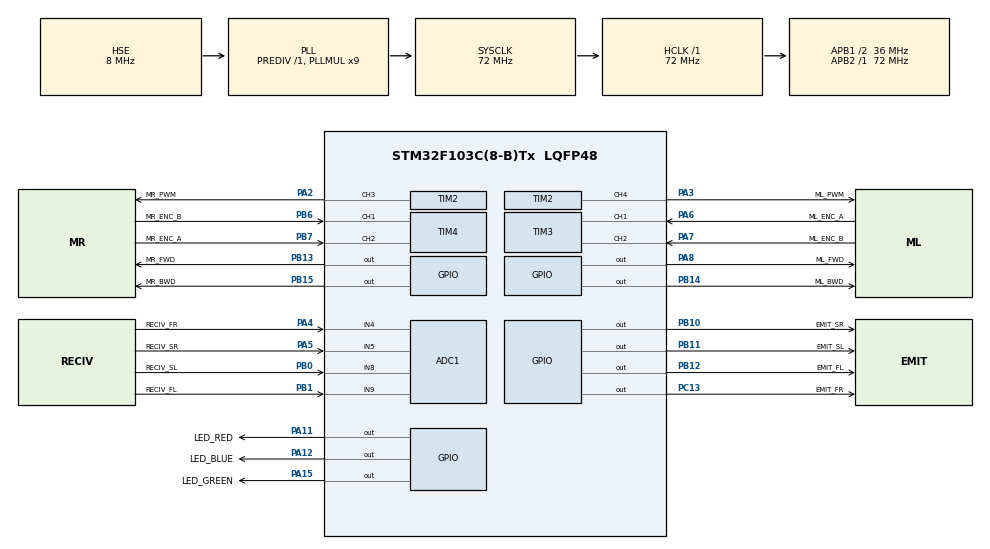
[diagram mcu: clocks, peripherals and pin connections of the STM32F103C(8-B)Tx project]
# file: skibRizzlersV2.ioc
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ADC1.Channel-0\#ChannelRegularConversion=ADC_CHANNEL_9
ADC1.NbrOfConversionFlag=1
ADC1.Rank-0\#ChannelRegularConversion=1
ADC1.SamplingTime-0\#ChannelRegularConversion=ADC_SAMPLETIME_1CYCLE_5
ADC1.master=1
Mcu.Family=STM32F1
Mcu.Name=STM32F103C(8-B)Tx
Mcu.Package=LQFP48
NVIC.PriorityGroup=NVIC_PRIORITYGROUP_4
NVIC.TIM3_IRQn=true\:0\:0\:false\:false\:true\:true\:true\:true
NVIC.TIM4_IRQn=true\:0\:0\:false\:false\:true\:true\:true\:true
PA11.GPIO_Label=LED_RED
PA11.Signal=GPIO_Output
PA12.GPIO_Label=LED_BLUE
PA12.Signal=GPIO_Output
PA13.Mode=Serial_Wire
PA13.Signal=SYS_JTMS-SWDIO
PA14.Mode=Serial_Wire
PA14.Signal=SYS_JTCK-SWCLK
PA15.GPIO_Label=LED_GREEN
PA15.Signal=GPIO_Output
PA2.GPIO_Label=MR_PWM
PA2.Signal=S_TIM2_CH3
PA3.GPIO_Label=ML_PWM
PA3.Signal=S_TIM2_CH4
PA4.GPIO_Label=RECIV_FR
PA4.Signal=ADCx_IN4
PA5.GPIO_Label=RECIV_SR
PA5.Signal=ADCx_IN5
PA6.GPIO_Label=ML_ENC_A
PA6.Signal=S_TIM3_CH1
PA7.GPIO_Label=ML_ENC_B
PA7.Signal=S_TIM3_CH2
PA8.GPIO_Label=ML_FWD
PA8.Signal=GPIO_Output
PB0.GPIO_Label=RECIV_SL
PB0.Signal=ADCx_IN8
PB1.GPIO_Label=RECIV_FL
PB1.Signal=ADCx_IN9
PB10.GPIO_Label=EMIT_SR
PB10.Signal=GPIO_Output
PB11.GPIO_Label=EMIT_SL
PB11.Signal=GPIO_Output
PB12.GPIO_Label=EMIT_FL
PB12.Signal=GPIO_Output
PB13.GPIO_Label=MR_FWD
PB13.Signal=GPIO_Output
PB14.GPIO_Label=ML_BWD
PB14.Signal=GPIO_Output
PB15.GPIO_Label=MR_BWD
PB15.Signal=GPIO_Output
PB6.GPIO_Label=MR_ENC_B
PB6.Signal=S_TIM4_CH1
PB7.GPIO_Label=MR_ENC_A
PB7.Signal=S_TIM4_CH2
PC13-TAMPER-RTC.GPIO_Label=EMIT_FR
PC13-TAMPER-RTC.Signal=GPIO_Output
PD0-OSC_IN.Mode=HSE-External-Oscillator
PD0-OSC_IN.Signal=RCC_OSC_IN
PD1-OSC_OUT.Mode=HSE-External-Oscillator
PD1-OSC_OUT.Signal=RCC_OSC_OUT
ProjectManager.HeapSize=0x200
ProjectManager.StackSize=0x400
ProjectManager.TargetToolchain=STM32CubeIDE
RCC.ADCPresc=RCC_ADCPCLK2_DIV6
RCC.AHBFreq_Value=72000000
RCC.APB1CLKDivider=RCC_HCLK_DIV2
RCC.APB1Freq_Value=36000000
RCC.APB1TimFreq_Value=72000000
RCC.APB2Freq_Value=72000000
RCC.APB2TimFreq_Value=72000000
RCC.HCLKFreq_Value=72000000
RCC.PLLMUL=RCC_PLL_MUL9
RCC.PLLSourceVirtual=RCC_PLLSOURCE_HSE
RCC.SYSCLKFreq_VALUE=72000000
RCC.SYSCLKSource=RCC_SYSCLKSOURCE_PLLCLK
RCC.USBFreq_Value=72000000
SH.ADCx_IN4.0=ADC1_IN4,IN4
SH.ADCx_IN5.0=ADC1_IN5,IN5
SH.ADCx_IN8.0=ADC1_IN8,IN8
SH.ADCx_IN9.0=ADC1_IN9,IN9
SH.S_TIM2_CH3.0=TIM2_CH3,PWM Generation3 CH3
SH.S_TIM2_CH4.0=TIM2_CH4,PWM Generation4 CH4
SH.S_TIM3_CH1.0=TIM3_CH1,Encoder_Interface
SH.S_TIM3_CH2.0=TIM3_CH2,Encoder_Interface
SH.S_TIM4_CH1.0=TIM4_CH1,Encoder_Interface
SH.S_TIM4_CH2.0=TIM4_CH2,Encoder_Interface
TIM2.AutoReloadPreload=TIM_AUTORELOAD_PRELOAD_ENABLE
TIM2.Channel-PWM\ Generation3\ CH3=TIM_CHANNEL_3
TIM2.Channel-PWM\ Generation4\ CH4=TIM_CHANNEL_4
TIM2.Period=2047
TIM3.EncoderMode=TIM_ENCODERMODE_TI12
TIM3.IC1Polarity=TIM_ICPOLARITY_FALLING
TIM4.EncoderMode=TIM_ENCODERMODE_TI12
TIM4.IC1Polarity=TIM_ICPOLARITY_FALLING
VP_TIM2_VS_ClockSourceINT.Mode=Internal
board=custom

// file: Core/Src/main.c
/* USER CODE BEGIN Header */
/**
  ******************************************************************************
  * @file           : main.c
  * @brief          : Main program body
  ******************************************************************************
  * @attention
  *
  * Copyright (c) 2026 STMicroelectronics.
  * All rights reserved.
  *
  * This software is licensed under terms that can be found in the LICENSE file
  * in the root directory of this software component.
  * If no LICENSE file comes with this software, it is provided AS-IS.
  *
  ******************************************************************************
  */
/* USER CODE END Header */
#include "main.h"

/* USER CODE BEGIN Includes */
#include "IR.h"
#include "motors.h"
#include "encoders.h"
/* USER CODE END Includes */

ADC_HandleTypeDef hadc1;

TIM_HandleTypeDef htim2;
TIM_HandleTypeDef htim3;
TIM_HandleTypeDef htim4;

/* USER CODE BEGIN PV */
float dis_FL;
float dis_FR;
float dis_SR;
float dis_SL;
/* USER CODE END PV */

void SystemClock_Config(void);
static void MX_GPIO_Init(void);
static void MX_ADC1_Init(void);
static void MX_TIM2_Init(void);
static void MX_TIM3_Init(void);
static void MX_TIM4_Init(void);

int main(void)
{

  /* MCU Configuration--------------------------------------------------------*/

  /* Reset of all peripherals, Initializes the Flash interface and the Systick. */
  HAL_Init();

  /* Configure the system clock */
  SystemClock_Config();

  /* Initialize all configured peripherals */
  MX_GPIO_Init();
  MX_ADC1_Init();
  MX_TIM2_Init();
  MX_TIM3_Init();
  MX_TIM4_Init();
  /* USER CODE BEGIN 2 */
  HAL_TIM_PWM_Start(&htim2, TIM_CHANNEL_3);
  HAL_TIM_PWM_Start(&htim2, TIM_CHANNEL_4);

  HAL_TIM_Encoder_Start_IT(&htim3, TIM_CHANNEL_ALL); //left encoder
  HAL_TIM_Encoder_Start_IT(&htim4, TIM_CHANNEL_ALL); //left encoder

  motor_direction(MOTOR_LEFT,  'F');
  motor_direction(MOTOR_RIGHT, 'F');
  /* USER CODE END 2 */

  /* Infinite loop */
  while (1)
  {
	/*manual motor testing*/
	//move forward
	motor_direction(MOTOR_LEFT,'F');
	motor_direction(MOTOR_RIGHT,'F');

	motor_speed(MOTOR_LEFT,1600);
	motor_speed(MOTOR_RIGHT,1600);

	motors_stop();
	HAL_Delay(1000);

	//move forward slower
	motor_direction(MOTOR_LEFT,'F');
	motor_direction(MOTOR_RIGHT,'F');
	motor_speed(MOTOR_LEFT,1400);
	motor_speed(MOTOR_RIGHT,1400);
	HAL_Delay(3000);

	motors_stop();
	HAL_Delay(1000);

	//move backward
	motor_direction(MOTOR_LEFT,'B');
	motor_direction(MOTOR_RIGHT,'B');

	motor_speed(MOTOR_LEFT,1800);
	motor_speed(MOTOR_RIGHT,1800);
	HAL_Delay(3000);

	motors_stop();
	HAL_Delay(1000);

	//move backward slower
	motor_direction(MOTOR_LEFT,'B');
	motor_direction(MOTOR_RIGHT,'B');
	motor_speed(MOTOR_LEFT,1400);
	motor_speed(MOTOR_RIGHT,1400);
	HAL_Delay(3000);

	motors_stop();
	HAL_Delay(1000);
  }
}

void SystemClock_Config(void)
{
  RCC_OscInitTypeDef RCC_OscInitStruct = {0};
  RCC_ClkInitTypeDef RCC_ClkInitStruct = {0};
  RCC_PeriphCLKInitTypeDef PeriphClkInit = {0};

  /** Initializes the RCC Oscillators according to the specified parameters
  * in the RCC_OscInitTypeDef structure.
  */
  RCC_OscInitStruct.OscillatorType = RCC_OSCILLATORTYPE_HSE;
  RCC_OscInitStruct.HSEState = RCC_HSE_ON;
  RCC_OscInitStruct.HSEPredivValue = RCC_HSE_PREDIV_DIV1;
  RCC_OscInitStruct.HSIState = RCC_HSI_ON;
  RCC_OscInitStruct.PLL.PLLState = RCC_PLL_ON;
  RCC_OscInitStruct.PLL.PLLSource = RCC_PLLSOURCE_HSE;
  RCC_OscInitStruct.PLL.PLLMUL = RCC_PLL_MUL9;
  if (HAL_RCC_OscConfig(&RCC_OscInitStruct) != HAL_OK)
  {
    Error_Handler();
  }

  /** Initializes the CPU, AHB and APB buses clocks
  */
  RCC_ClkInitStruct.ClockType = RCC_CLOCKTYPE_HCLK|RCC_CLOCKTYPE_SYSCLK
                              |RCC_CLOCKTYPE_PCLK1|RCC_CLOCKTYPE_PCLK2;
  RCC_ClkInitStruct.SYSCLKSource = RCC_SYSCLKSOURCE_PLLCLK;
  RCC_ClkInitStruct.AHBCLKDivider = RCC_SYSCLK_DIV1;
  RCC_ClkInitStruct.APB1CLKDivider = RCC_HCLK_DIV2;
  RCC_ClkInitStruct.APB2CLKDivider = RCC_HCLK_DIV1;

  if (HAL_RCC_ClockConfig(&RCC_ClkInitStruct, FLASH_LATENCY_2) != HAL_OK)
  {
    Error_Handler();
  }
  PeriphClkInit.PeriphClockSelection = RCC_PERIPHCLK_ADC;
  PeriphClkInit.AdcClockSelection = RCC_ADCPCLK2_DIV6;
  if (HAL_RCCEx_PeriphCLKConfig(&PeriphClkInit) != HAL_OK)
  {
    Error_Handler();
  }
}

static void MX_ADC1_Init(void)
{

  ADC_ChannelConfTypeDef sConfig = {0};

  /** Common config
  */
  hadc1.Instance = ADC1;
  hadc1.Init.ScanConvMode = ADC_SCAN_DISABLE;
  hadc1.Init.ContinuousConvMode = DISABLE;
  hadc1.Init.DiscontinuousConvMode = DISABLE;
  hadc1.Init.ExternalTrigConv = ADC_SOFTWARE_START;
  hadc1.Init.DataAlign = ADC_DATAALIGN_RIGHT;
  hadc1.Init.NbrOfConversion = 1;
  if (HAL_ADC_Init(&hadc1) != HAL_OK)
  {
    Error_Handler();
  }

  /** Configure Regular Channel
  */
  sConfig.Channel = ADC_CHANNEL_9;
  sConfig.Rank = ADC_REGULAR_RANK_1;
  sConfig.SamplingTime = ADC_SAMPLETIME_1CYCLE_5;
  if (HAL_ADC_ConfigChannel(&hadc1, &sConfig) != HAL_OK)
  {
    Error_Handler();
  }

}

static void MX_TIM2_Init(void)
{

  TIM_ClockConfigTypeDef sClockSourceConfig = {0};
  TIM_MasterConfigTypeDef sMasterConfig = {0};
  TIM_OC_InitTypeDef sConfigOC = {0};

  htim2.Instance = TIM2;
  htim2.Init.Prescaler = 0;
  htim2.Init.CounterMode = TIM_COUNTERMODE_UP;
  htim2.Init.Period = 2047;
  htim2.Init.ClockDivision = TIM_CLOCKDIVISION_DIV1;
  htim2.Init.AutoReloadPreload = TIM_AUTORELOAD_PRELOAD_ENABLE;
  if (HAL_TIM_Base_Init(&htim2) != HAL_OK)
  {
    Error_Handler();
  }
  sClockSourceConfig.ClockSource = TIM_CLOCKSOURCE_INTERNAL;
  if (HAL_TIM_ConfigClockSource(&htim2, &sClockSourceConfig) != HAL_OK)
  {
    Error_Handler();
  }
  if (HAL_TIM_PWM_Init(&htim2) != HAL_OK)
  {
    Error_Handler();
  }
  sMasterConfig.MasterOutputTrigger = TIM_TRGO_RESET;
  sMasterConfig.MasterSlaveMode = TIM_MASTERSLAVEMODE_DISABLE;
  if (HAL_TIMEx_MasterConfigSynchronization(&htim2, &sMasterConfig) != HAL_OK)
  {
    Error_Handler();
  }
  sConfigOC.OCMode = TIM_OCMODE_PWM1;
  sConfigOC.Pulse = 0;
  sConfigOC.OCPolarity = TIM_OCPOLARITY_HIGH;
  sConfigOC.OCFastMode = TIM_OCFAST_DISABLE;
  if (HAL_TIM_PWM_ConfigChannel(&htim2, &sConfigOC, TIM_CHANNEL_3) != HAL_OK)
  {
    Error_Handler();
  }
  if (HAL_TIM_PWM_ConfigChannel(&htim2, &sConfigOC, TIM_CHANNEL_4) != HAL_OK)
  {
    Error_Handler();
  }
  HAL_TIM_MspPostInit(&htim2);

}

static void MX_TIM3_Init(void)
{

  TIM_Encoder_InitTypeDef sConfig = {0};
  TIM_MasterConfigTypeDef sMasterConfig = {0};

  htim3.Instance = TIM3;
  htim3.Init.Prescaler = 0;
  htim3.Init.CounterMode = TIM_COUNTERMODE_UP;
  htim3.Init.Period = 65535;
  htim3.Init.ClockDivision = TIM_CLOCKDIVISION_DIV1;
  htim3.Init.AutoReloadPreload = TIM_AUTORELOAD_PRELOAD_DISABLE;
  sConfig.EncoderMode = TIM_ENCODERMODE_TI12;
  sConfig.IC1Polarity = TIM_ICPOLARITY_FALLING;
  sConfig.IC1Selection = TIM_ICSELECTION_DIRECTTI;
  sConfig.IC1Prescaler = TIM_ICPSC_DIV1;
  sConfig.IC1Filter = 0;
  sConfig.IC2Polarity = TIM_ICPOLARITY_RISING;
  sConfig.IC2Selection = TIM_ICSELECTION_DIRECTTI;
  sConfig.IC2Prescaler = TIM_ICPSC_DIV1;
  sConfig.IC2Filter = 0;
  if (HAL_TIM_Encoder_Init(&htim3, &sConfig) != HAL_OK)
  {
    Error_Handler();
  }
  sMasterConfig.MasterOutputTrigger = TIM_TRGO_RESET;
  sMasterConfig.MasterSlaveMode = TIM_MASTERSLAVEMODE_DISABLE;
  if (HAL_TIMEx_MasterConfigSynchronization(&htim3, &sMasterConfig) != HAL_OK)
  {
    Error_Handler();
  }

}

static void MX_TIM4_Init(void)
{

  TIM_Encoder_InitTypeDef sConfig = {0};
  TIM_MasterConfigTypeDef sMasterConfig = {0};

  htim4.Instance = TIM4;
  htim4.Init.Prescaler = 0;
  htim4.Init.CounterMode = TIM_COUNTERMODE_UP;
  htim4.Init.Period = 65535;
  htim4.Init.ClockDivision = TIM_CLOCKDIVISION_DIV1;
  htim4.Init.AutoReloadPreload = TIM_AUTORELOAD_PRELOAD_DISABLE;
  sConfig.EncoderMode = TIM_ENCODERMODE_TI12;
  sConfig.IC1Polarity = TIM_ICPOLARITY_FALLING;
  sConfig.IC1Selection = TIM_ICSELECTION_DIRECTTI;
  sConfig.IC1Prescaler = TIM_ICPSC_DIV1;
  sConfig.IC1Filter = 0;
  sConfig.IC2Polarity = TIM_ICPOLARITY_RISING;
  sConfig.IC2Selection = TIM_ICSELECTION_DIRECTTI;
  sConfig.IC2Prescaler = TIM_ICPSC_DIV1;
  sConfig.IC2Filter = 0;
  if (HAL_TIM_Encoder_Init(&htim4, &sConfig) != HAL_OK)
  {
    Error_Handler();
  }
  sMasterConfig.MasterOutputTrigger = TIM_TRGO_RESET;
  sMasterConfig.MasterSlaveMode = TIM_MASTERSLAVEMODE_DISABLE;
  if (HAL_TIMEx_MasterConfigSynchronization(&htim4, &sMasterConfig) != HAL_OK)
  {
    Error_Handler();
  }

}

static void MX_GPIO_Init(void)
{
  GPIO_InitTypeDef GPIO_InitStruct = {0};

  /* GPIO Ports Clock Enable */
  __HAL_RCC_GPIOC_CLK_ENABLE();
  __HAL_RCC_GPIOD_CLK_ENABLE();
  __HAL_RCC_GPIOA_CLK_ENABLE();
  __HAL_RCC_GPIOB_CLK_ENABLE();

  /*Configure GPIO pin Output Level */
  HAL_GPIO_WritePin(EMIT_FR_GPIO_Port, EMIT_FR_Pin, GPIO_PIN_RESET);

  /*Configure GPIO pin Output Level */
  HAL_GPIO_WritePin(GPIOB, EMIT_SR_Pin|EMIT_SL_Pin|EMIT_FL_Pin|MR_FWD_Pin
                          |ML_BWD_Pin|MR_BWD_Pin, GPIO_PIN_RESET);

  /*Configure GPIO pin Output Level */
  HAL_GPIO_WritePin(GPIOA, ML_FWD_Pin|LED_RED_Pin|LED_BLUE_Pin|LED_GREEN_Pin, GPIO_PIN_RESET);

  /*Configure GPIO pin : EMIT_FR_Pin */
  GPIO_InitStruct.Pin = EMIT_FR_Pin;
  GPIO_InitStruct.Mode = GPIO_MODE_OUTPUT_PP;
  GPIO_InitStruct.Pull = GPIO_NOPULL;
  GPIO_InitStruct.Speed = GPIO_SPEED_FREQ_LOW;
  HAL_GPIO_Init(EMIT_FR_GPIO_Port, &GPIO_InitStruct);

  /*Configure GPIO pins : EMIT_SR_Pin EMIT_SL_Pin EMIT_FL_Pin MR_FWD_Pin
                           ML_BWD_Pin MR_BWD_Pin */
  GPIO_InitStruct.Pin = EMIT_SR_Pin|EMIT_SL_Pin|EMIT_FL_Pin|MR_FWD_Pin
                          |ML_BWD_Pin|MR_BWD_Pin;
  GPIO_InitStruct.Mode = GPIO_MODE_OUTPUT_PP;
  GPIO_InitStruct.Pull = GPIO_NOPULL;
  GPIO_InitStruct.Speed = GPIO_SPEED_FREQ_LOW;
  HAL_GPIO_Init(GPIOB, &GPIO_InitStruct);

  /*Configure GPIO pins : ML_FWD_Pin LED_RED_Pin LED_BLUE_Pin LED_GREEN_Pin */
  GPIO_InitStruct.Pin = ML_FWD_Pin|LED_RED_Pin|LED_BLUE_Pin|LED_GREEN_Pin;
  GPIO_InitStruct.Mode = GPIO_MODE_OUTPUT_PP;
  GPIO_InitStruct.Pull = GPIO_NOPULL;
  GPIO_InitStruct.Speed = GPIO_SPEED_FREQ_LOW;
  HAL_GPIO_Init(GPIOA, &GPIO_InitStruct);

}

void Error_Handler(void)
{
  __disable_irq();
  while (1)
  {
  }
}
